# ATSAME53N20A register map
Vendor: Microchip Technology Inc.; Series: SAME53; File version: A
CPU: CM4 r0p1, little endian, MPU, FPU, 3 interrupt priority bits, 137 interrupts
Registers are 32-bit, read-write, reset 0x0 unless marked. A register's access mark holds for its fields unless they carry their own. Offsets are from the block's base; [hi:lo] are bit positions; {n}, {i} and the like mark numbered series.

## EIC — External Interrupt Controller
Base 0x40002800; register names take the prefix EIC_
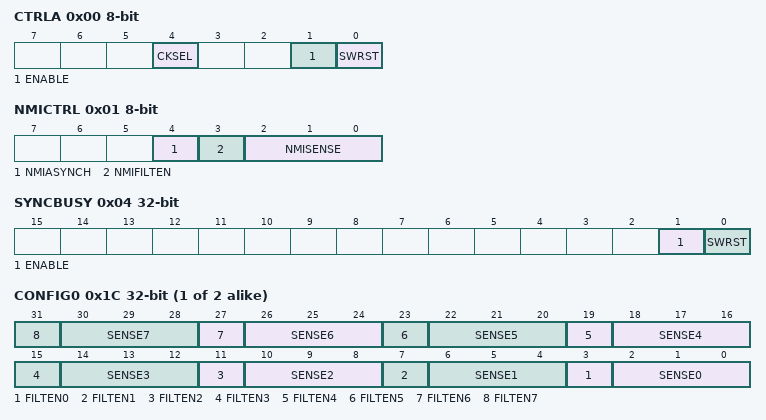
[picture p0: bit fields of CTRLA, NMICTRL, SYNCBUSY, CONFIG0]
0x00 CTRLA 8-bit — Control A
  [4] CKSEL — Clock Selection
  [1] ENABLE
  [0] SWRST wo — Software Reset
0x01 NMICTRL 8-bit — Non-Maskable Interrupt Control
  [4] NMIASYNCH — Asynchronous Edge Detection Mode
  [3] NMIFILTEN — Non-Maskable Interrupt Filter Enable
  [2:0] NMISENSE — Non-Maskable Interrupt Sense Configuration
    0=NONE (No detection); 1=RISE (Rising-edge detection); 2=FALL (Falling-edge detection); 3=BOTH (Both-edges detection); 4=HIGH (High-level detection); 5=LOW (Low-level detection)
0x02 NMIFLAG 16-bit — Non-Maskable Interrupt Flag Status and Clear
  [0] NMI — Non-Maskable Interrupt
0x04 SYNCBUSY ro — Synchronization Busy
  [1] ENABLE — Enable Synchronization Busy Status
  [0] SWRST — Software Reset Synchronization Busy Status
0x08 EVCTRL — Event Control
  [15:0] EXTINTEO — External Interrupt Event Output Enable
0x0C INTENCLR — Interrupt Enable Clear
  [15:0] EXTINT — External Interrupt Enable
0x10 INTENSET — Interrupt Enable Set
  [15:0] EXTINT — External Interrupt Enable
0x14 INTFLAG — Interrupt Flag Status and Clear
  [15:0] EXTINT — External Interrupt
0x18 ASYNCH — External Interrupt Asynchronous Mode
  [15:0] ASYNCH — Asynchronous Edge Detection Mode
{0x1C+4i} CONFIG{i} (i=0..1) — External Interrupt Sense Configuration
  [4n+3] FILTEN{n} (n=0..7) — Filter Enable {n}
  [4n+2:4n] SENSE{n} (n=0..7) — Input Sense Configuration {n}
    0=NONE (No detection); 1=RISE (Rising edge detection); 2=FALL (Falling edge detection); 3=BOTH (Both edges detection); 4=HIGH (High level detection); 5=LOW (Low level detection)
0x30 DEBOUNCEN — Debouncer Enable
  [15:0] DEBOUNCEN
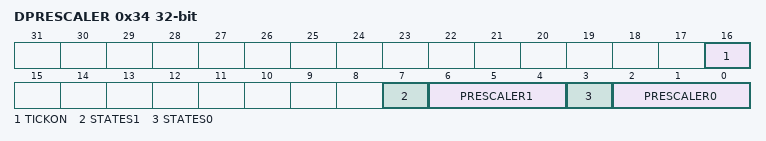
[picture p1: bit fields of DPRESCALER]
0x34 DPRESCALER — Debouncer Prescaler
  [16] TICKON — Pin Sampler frequency selection
  [7] STATES1 — Debouncer number of states
  [6:4] PRESCALER1 — Debouncer Prescaler
  [3] STATES0 — Debouncer number of states
  [2:0] PRESCALER0 — Debouncer Prescaler
0x38 PINSTATE ro
  [15:0] PINSTATE

## EVSYS — Event System Interface
Base 0x4100E000; register names take the prefix EVSYS_
0x00 CTRLA 8-bit — Control
  [0] SWRST wo — Software Reset
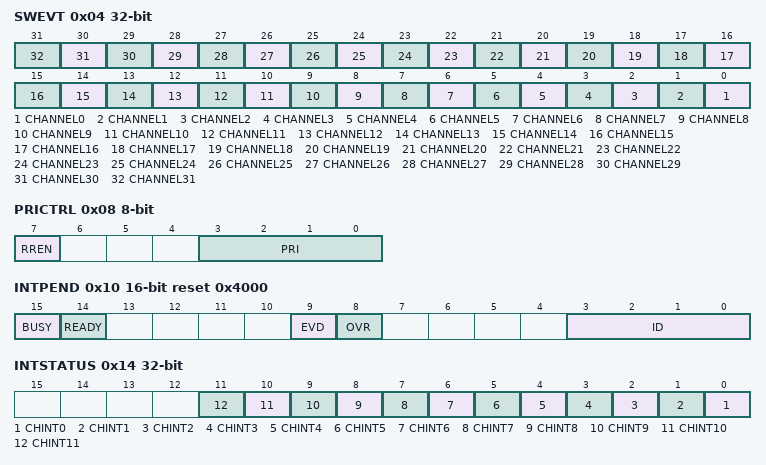
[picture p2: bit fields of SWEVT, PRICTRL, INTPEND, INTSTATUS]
0x04 SWEVT wo — Software Event
  [n] CHANNEL{n} (n=0..31) — Channel {n} Software Selection
0x08 PRICTRL 8-bit — Priority Control
  [7] RREN — Round-Robin Scheduling Enable
  [3:0] PRI — Channel Priority Number
0x10 INTPEND 16-bit reset 0x4000 — Channel Pending Interrupt
  [15] BUSY ro
  [14] READY ro
  [9] EVD — Channel Event Detected
  [8] OVR — Channel Overrun
  [3:0] ID — Channel ID
0x14 INTSTATUS ro — Interrupt Status
  [n] CHINT{n} (n=0..11) — Channel {n} Pending Interrupt
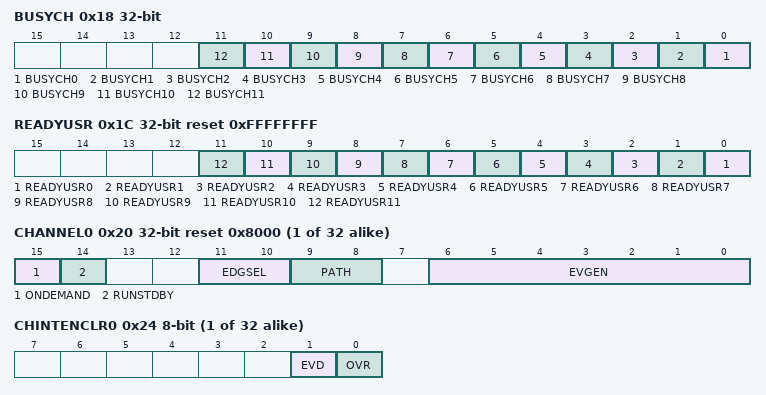
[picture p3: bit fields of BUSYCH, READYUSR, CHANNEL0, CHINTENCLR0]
0x18 BUSYCH ro — Busy Channels
  [n] BUSYCH{n} (n=0..11) — Busy Channel {n}
0x1C READYUSR ro reset 0xFFFFFFFF — Ready Users
  [n] READYUSR{n} (n=0..11) — Ready User for Channel {n}
{0x20+8i} CHANNEL{i} (i=0..31) reset 0x8000 — Channel n Control
  [15] ONDEMAND — Generic Clock On Demand
  [14] RUNSTDBY — Run in standby
  [11:10] EDGSEL — Edge Detection Selection
    0=NO_EVT_OUTPUT (No event output when using the resynchronized or synchronous path); 1=RISING_EDGE (Event detection only on the rising edge of the signal from the event generator when using the resynchronized or synchronous path); 2=FALLING_EDGE (Event detection only on the falling edge of the signal from the event generator when using the resynchronized or synchronous path); 3=BOTH_EDGES (Event detection on rising and falling edges of the signal from the event generator when using the resynchronized or synchronous path)
  [9:8] PATH — Path Selection
    0=SYNCHRONOUS (Synchronous path); 1=RESYNCHRONIZED (Resynchronized path); 2=ASYNCHRONOUS (Asynchronous path)
  [6:0] EVGEN — Event Generator Selection
{0x24+8i} CHINTENCLR{i} (i=0..31) 8-bit — Channel n Interrupt Enable Clear
  [1] EVD — Channel Event Detected Interrupt Disable
  [0] OVR — Channel Overrun Interrupt Disable
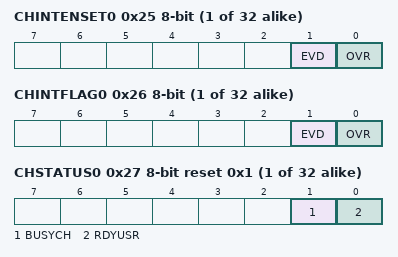
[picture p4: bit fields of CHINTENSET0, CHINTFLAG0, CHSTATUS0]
{0x25+8i} CHINTENSET{i} (i=0..31) 8-bit — Channel n Interrupt Enable Set
  [1] EVD — Channel Event Detected Interrupt Enable
  [0] OVR — Channel Overrun Interrupt Enable
{0x26+8i} CHINTFLAG{i} (i=0..31) 8-bit — Channel n Interrupt Flag Status and Clear
  [1] EVD — Channel Event Detected
  [0] OVR — Channel Overrun
{0x27+8i} CHSTATUS{i} (i=0..31) 8-bit ro reset 0x1 — Channel n Status
  [1] BUSYCH — Busy Channel
  [0] RDYUSR — Ready User
{0x120+4i} USER{i} (i=0..66) — User Multiplexer n
  [5:0] CHANNEL — Channel Event Selection

## Notices in the file
Copyright (c) 2018 Microchip Technology Inc.
SPDX-License-Identifier: Apache-2.0
Licensed under the Apache License, Version 2.0 (the "License");
you may not use this file except in compliance with the License.
You may obtain a copy of the License at
http://www.apache.org/licenses/LICENSE-2.0
Unless required by applicable law or agreed to in writing, software
distributed under the License is distributed on an "AS IS" BASIS,
WITHOUT WARRANTIES OR CONDITIONS OF ANY KIND, either express or implied.
See the License for the specific language governing permissions and
limitations under the License.
